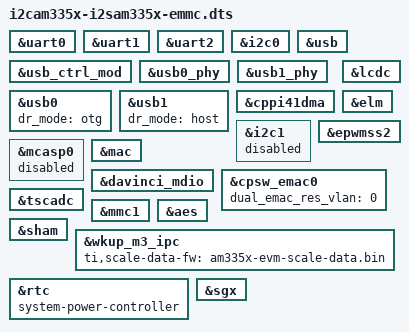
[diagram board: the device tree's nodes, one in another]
/*
 * Copyright (C) 2012 Texas Instruments Incorporated - http://www.ti.com/
 *
 * This program is free software; you can redistribute it and/or modify
 * it under the terms of the GNU General Public License version 2 as
 * published by the Free Software Foundation.
 */
/dts-v1/;

#include "i2s-am335x-emmc.dtsi"
#include "i2cam335x-i2sam335x-emmc.dtsi"

&uart0 {
	status = "okay";
};

&uart1 {
	status = "okay";
};

&uart2 {
	status = "okay";
};

&i2c0 {
	status = "okay";
};

&usb {
	status = "okay";
};

&usb_ctrl_mod {
	status = "okay";
};

&usb0_phy {
	status = "okay";
};

&usb1_phy {
	status = "okay";
};

&usb0 {
	dr_mode = "otg";
	status = "okay";
};

&usb1 {
	dr_mode = "host";
	status = "okay";
};

&cppi41dma  {
	status = "okay";
};

&i2c1 {
	status = "disabled";
};

&lcdc {
	status = "okay";
};

&elm {
	status = "okay";
};

&epwmss2 {
	status = "okay";
};

&mcasp0 {
	status = "disabled";
};

&mac {
	status = "okay";
};

&davinci_mdio {
	status = "okay";
};

&cpsw_emac0 {
	dual_emac_res_vlan=<0>;
};

&tscadc {
	status = "okay";
};

&mmc1 {
	status = "okay";
};

&sham {
	status = "okay";
};

&aes {
	status = "okay";
};

&wkup_m3_ipc {
	ti,scale-data-fw = "am335x-evm-scale-data.bin";
};

&rtc {
	system-power-controller;
};

&sgx {
	status = "okay";
};
